# GPMC0_CFG register map
Vendor: Texas Instruments
Peripheral module from a debugger description file (folder J722S).
Registers are 32-bit, access not given, reset 0x0 unless marked. A register's access mark holds for its fields unless they carry their own. Offsets are as the file gives them; lines under a group give offsets from that group; [hi:lo] are bit positions; {n}, {i} and the like mark numbered series; 'fields as' and 'values as' point back to an identical list; <NAME> marks a mode.

## GPMC0_CFG
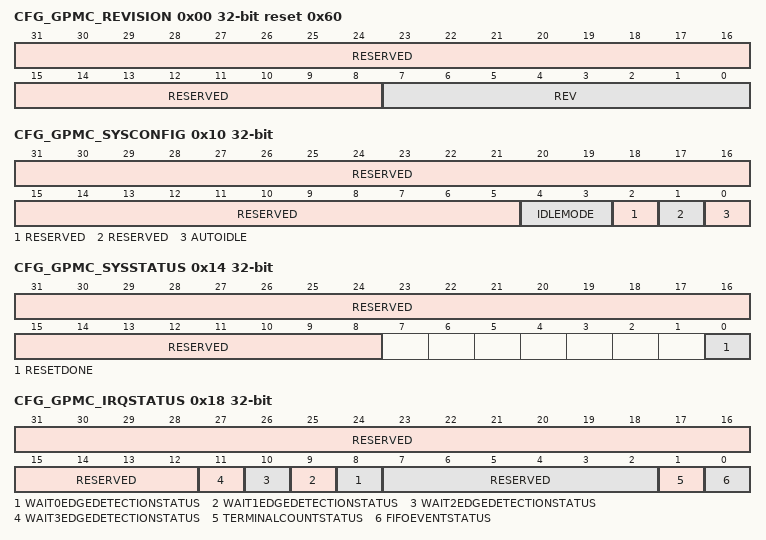
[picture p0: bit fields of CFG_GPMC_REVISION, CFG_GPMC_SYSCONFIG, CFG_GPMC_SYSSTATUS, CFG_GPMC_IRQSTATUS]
0x00 CFG_GPMC_REVISION reset 0x60 — This register contains the IP revision code
  [31:8] RESERVED — Reads returns 0 (access N/A)
  [7:0] REV ro — IP revision [7:4] Major revision [3:0] Minor revision Examples: 0x10 for 1.0, 0x21 for 2.1
0x10 CFG_GPMC_SYSCONFIG — This register controls the various parameters of the OCP interface
  [31:5] RESERVED — Write 0's for future compatibility Reads return 0 (access N/A)
  [4:3] IDLEMODE rw
  [2] RESERVED — Write 0 for future compatibility Reads returns 0 (access N/A)
  [1] RESERVED — This bit must be kept 0 for normal functioning of the IP. Do not set this bit to 1 (access N/A)
  [0] AUTOIDLE rw — Internal OCP clock gating strategy
0x14 CFG_GPMC_SYSSTATUS — This register provides status information about the module, excluding the interrupt status information
  [31:8] RESERVED — Reads returns 0 (access N/A)
  [0] RESETDONE ro — Internal reset monitoring
0x18 CFG_GPMC_IRQSTATUS — This interrupt status register regroups all the status of the module internal events that can generate an interrupt.
  [31:12] RESERVED — Write 0's for future compatibility. Read returns 0 (access N/A)
  [n+8] WAIT{n}EDGEDETECTIONSTATUS (n=0..3) — Status of the Wait{n} Edge Detection interrupt (access R/W1TC)
  [7:2] RESERVED — Write 0's for future compatibility. Read returns 0 (access N/A)
  [1] TERMINALCOUNTSTATUS — Status of the TerminalCountEvent interrupt (access R/W1TC)
  [0] FIFOEVENTSTATUS — Status of the FIFOEvent interrupt (access R/W1TC)
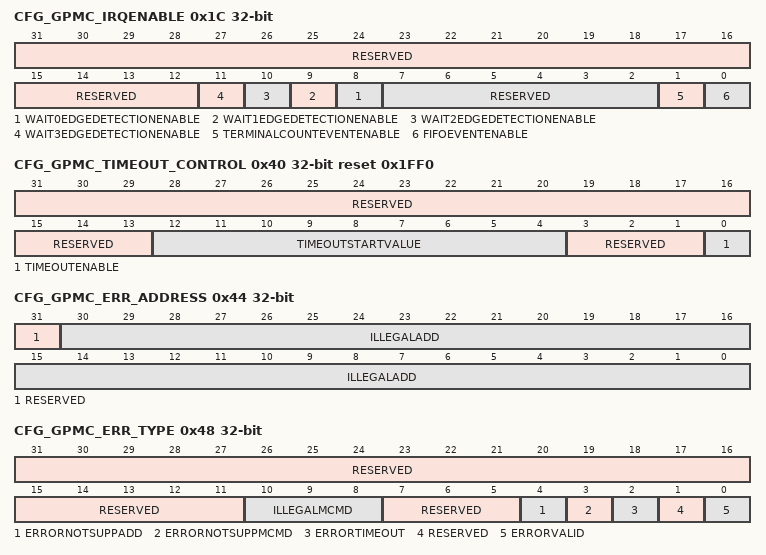
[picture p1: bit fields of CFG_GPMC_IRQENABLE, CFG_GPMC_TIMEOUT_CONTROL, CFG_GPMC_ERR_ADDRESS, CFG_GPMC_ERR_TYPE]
0x1C CFG_GPMC_IRQENABLE — The interrupt enable register allows to mask/unmask the module internal sources of interrupt, on a event-by-event basis.
  [31:12] RESERVED — Write 0's for future compatibility. Read returns 0 (access N/A)
  [n+8] WAIT{n}EDGEDETECTIONENABLE rw (n=0..3) — Enables the Wait{n} Edge Detection interrupt
  [7:2] RESERVED — Write 0's for future compatibility. Read returns 0 (access N/A)
  [1] TERMINALCOUNTEVENTENABLE rw — Enables TerminalCountEvent interrupt issuing in pre-fetch or write posting mode
  [0] FIFOEVENTENABLE rw — Enables the FIFOEvent interrupt
0x40 CFG_GPMC_TIMEOUT_CONTROL reset 0x1FF0 — The GPMC_TIMEOUT_CONTROL register allows the user to set the start value of the timeout counter
  [31:13] RESERVED — Write 0's for future compatibility. Read returns 0 (access N/A)
  [12:4] TIMEOUTSTARTVALUE rw — Start value of the time-out counter [0x000 corresponds to 0 GPMC.FCLK cycle, 0x001 corresponds to 1 GmpcClk cycle, &, 0x1FF corresponds to 511 GPMC.FCLK cyles.]
  [3:1] RESERVED — Write 0's for future compatibility. Read returns 0 (access N/A)
  [0] TIMEOUTENABLE rw — Enable bit of the TimeOut feature
0x44 CFG_GPMC_ERR_ADDRESS — The GPMC_ERR_ADDRESS register stores the address of the illegal access when an error occurs
  [31] RESERVED — Write 0's for future compatibility. Read returns 0 (access N/A)
  [30:0] ILLEGALADD ro — Address of illegal access : A30[0 for memory region, 1 for GPMC register region] and A29-A0[1 GBytes maximum]
0x48 CFG_GPMC_ERR_TYPE — The GPMC_ERR_TYPE register stores the type of error when an error occurs
  [31:11] RESERVED — Write 0's for future compatibility. Read returns 0 (access N/A)
  [10:8] ILLEGALMCMD ro — System Command of the transaction that caused the error
  [7:5] RESERVED — Write 0's for future compatibility. Read returns 0 (access N/A)
  [4] ERRORNOTSUPPADD ro — Not supported Address error
  [3] ERRORNOTSUPPMCMD ro — Not supported Command error
  [2] ERRORTIMEOUT ro — Time-out error
  [1] RESERVED — Write 0's for future compatibility. Read returns 0 (access N/A)
  [0] ERRORVALID — Error validity status - Must be explicitely cleared with a write 1 transaction (access R/W1TC)
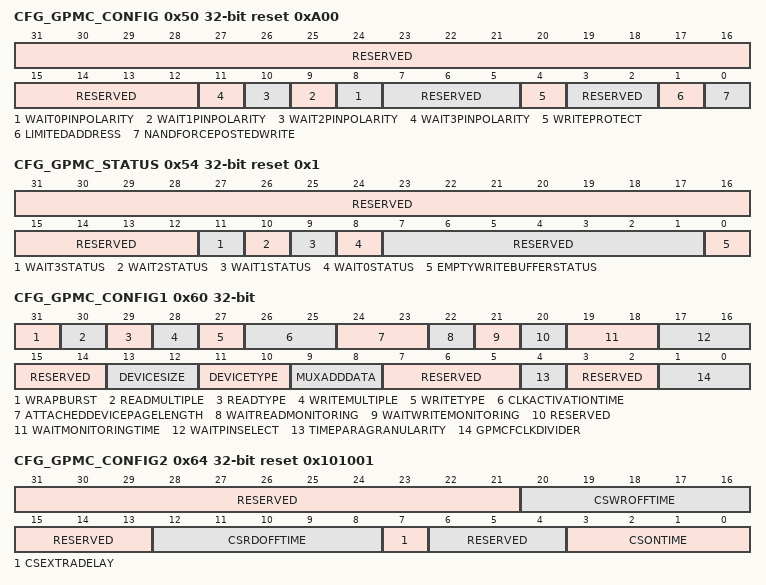
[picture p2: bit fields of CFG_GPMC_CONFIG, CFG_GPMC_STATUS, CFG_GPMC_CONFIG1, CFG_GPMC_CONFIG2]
0x50 CFG_GPMC_CONFIG reset 0xA00 — The configuration register allows global configuration of the GPMC
  [31:12] RESERVED — Write 0's for future compatibility. Read returns 0 (access N/A)
  [n+8] WAIT{n}PINPOLARITY rw (n=0..3) — Selects the polarity of input pin WAIT{n}
  [7:5] RESERVED — Write 0's for future compatibility. Read returns 0 (access N/A)
  [4] WRITEPROTECT rw — Controls the WP output pin level
  [3:2] RESERVED — Write 0's for future compatibility. Read returns 0 (access N/A)
  [1] LIMITEDADDRESS rw — Limited Address device support
  [0] NANDFORCEPOSTEDWRITE rw — Enables the Force Posted Write feature to NAND Cmd/Add/Data location
0x54 CFG_GPMC_STATUS reset 0x1 — The status register provides global status bits of the GPMC
  [31:12] RESERVED — Write 0's for future compatibility. Read returns 0 (access N/A)
  [11] WAIT3STATUS ro — Is a copy of input pin WAIT3. [Reset value is WAIT3 input pin sampled at IC reset]
  [10] WAIT2STATUS ro — Is a copy of input pin WAIT2. [Reset value is WAIT2 input pin sampled at IC reset]
  [9] WAIT1STATUS ro — Is a copy of input pin WAIT1. [Reset value is WAIT1 input pin sampled at IC reset]
  [8] WAIT0STATUS ro — Is a copy of input pin WAIT0. [Reset value is WAIT0 input pin sampled at IC reset]
  [7:1] RESERVED — Write 0's for future compatibility Reads returns 0 (access N/A)
  [0] EMPTYWRITEBUFFERSTATUS ro — Stores the empty status of the write buffer
0x60 CFG_GPMC_CONFIG1 — The configuration 1 register sets signal control parameters per chip select
  [31] WRAPBURST rw — Enables the wrapping burst capability. Must be set if the attached device is configured in wrapping burst
  [30] READMULTIPLE rw — Selects the read single or multiple access
  [29] READTYPE rw — Selects the read mode operation
  [28] WRITEMULTIPLE rw — Selects the write single or multiple access
  [27] WRITETYPE rw — Selects the write mode operation
  [26:25] CLKACTIVATIONTIME rw — Output GPMC.CLK activation time
  [24:23] ATTACHEDDEVICEPAGELENGTH rw — Specifies the attached device page [burst] length
  [22] WAITREADMONITORING rw — Selects the Wait monitoring configuration for Read accesses [Reset value is BOOTWAITEN input pin sampled at IC reset]
  [21] WAITWRITEMONITORING rw — Selects the Wait monitoring configuration for Write accesses
  [20] RESERVED — Write 0's for future compatibility. Read returns 0 (access N/A)
  [19:18] WAITMONITORINGTIME rw — Selects input pin Wait monitoring time
  [17:16] WAITPINSELECT rw — Selects the input WAIT pin for this chip select [Reset value is BOOTWAITSELECT input pin sampled at IC reset for CS0 and 0 for CS1-7]
  [15:14] RESERVED — Write 0's for future compatibility. Read returns 0 (access N/A)
  [13:12] DEVICESIZE rw — Selects the device size attached [Reset value is BOOTDEVICESIZE input pin sampled at IC reset for CS0 and 01 for CS1-7]
  [11:10] DEVICETYPE rw — Selects the attached device type
  [9:8] MUXADDDATA rw — Enables the Address and data multiplexed protocol [Reset value is CS0MUXDEVICE input pin sampled at IC reset for CS0 and 0 for CS1-7]
  [7:5] RESERVED — Write 0's for future compatibility. Read returns 0 (access N/A)
  [4] TIMEPARAGRANULARITY rw — Signals timing latencies scalar factor [Rd/WRCycleTime, AccessTime, PageBurstAccessTime, CSOnTime, CSRd/WrOffTime, ADVOnTime, ADVRd/WrOffTime, OEOnTime, OEOffTime, WEOnTime, WEOffTime, Cycle2CycleDelay, BusTurnAround, TimeOutStartValue]
  [3:2] RESERVED — Write 0's for future compatibility. Read returns 0 (access N/A)
  [1:0] GPMCFCLKDIVIDER rw — Divides the GPMC.FCLK clock
0x64 CFG_GPMC_CONFIG2 reset 0x101001 — Chip-select signal timing parameter configuration
  [31:21] RESERVED — Write 0's for future compatibility Reads returns 0 (access N/A)
  [20:16] CSWROFFTIME rw — CS# de-assertion time from start cycle time for write accesses [0x00 corresponds to 0 GPMC.FCLK cycle, 0x01 corresponds to 1 GPMC.FCLK cycle, &, 0x1F corresponds to 31 GPMC.FCLK cycles]
  [15:13] RESERVED — Write 0's for future compatibility. Read returns 0 (access N/A)
  [12:8] CSRDOFFTIME rw — CS# de-assertion time from start cycle time for read accesses [0x00 corresponds to 0 GPMC.FCLK cycle, 0x01 corresponds to 1 GPMC.FCLK cycle, &, 0x1F corresponds to 31 GPMC.FCLK cycles]
  [7] CSEXTRADELAY rw — CS# Add Extra Half GPMC.FCLK cycle
  [6:4] RESERVED — Write 0's for future compatibility. Read returns 0 (access N/A)
  [3:0] CSONTIME rw — CS# assertion time from start cycle time [0x0 corresponds to 0 GPMC.FCLK cycle, 0x1 corresponds to 1 GPMC.FCLK cycle, &, 0xF corresponds to 15 GPMC.FCLK cycles]
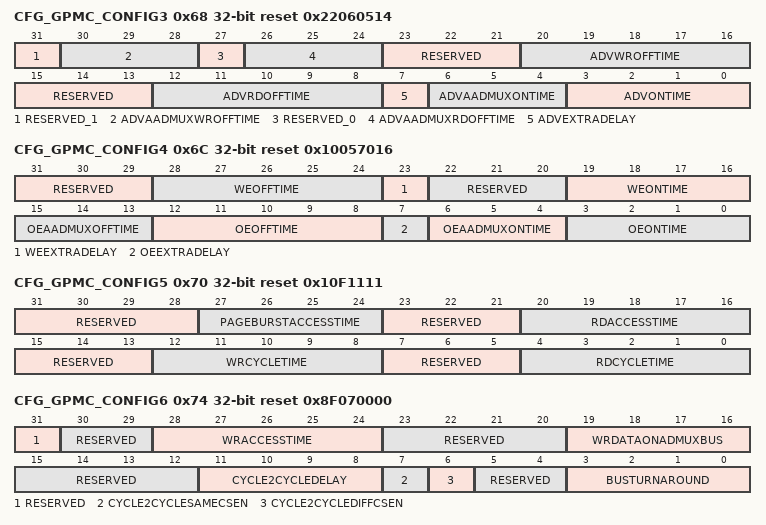
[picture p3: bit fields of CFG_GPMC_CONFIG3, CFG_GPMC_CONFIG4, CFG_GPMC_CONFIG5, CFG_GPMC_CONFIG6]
0x68 CFG_GPMC_CONFIG3 reset 0x22060514 — ADV# signal timing parameter configuration
  [31] RESERVED_1 ro — Write 0's for future compatibility. Read returns 0
  [30:28] ADVAADMUXWROFFTIME rw — ADV# de-assertion for first address phase when using the AAD-Mux protocol
  [27] RESERVED_0 ro — Write 0's for future compatibility. Read returns 0
  [26:24] ADVAADMUXRDOFFTIME rw — ADV# assertion for first address phase when using the AAD-Mux protocol
  [23:21] RESERVED — Write 0's for future compatibility. Read returns 0 (access N/A)
  [20:16] ADVWROFFTIME rw — ADV# de-assertion time from start cycle time for write accesses [0x00 corresponds to 0 GPMC.FCLK cycle, 0x01 corresponds to 1 GPMC.FCLK cycle, &, 0x1F corresponds to 31 GPMC.FCLK cycles]
  [15:13] RESERVED — Write 0's for future compatibility. Read returns 0 (access N/A)
  [12:8] ADVRDOFFTIME rw — ADV# de-assertion time from start cycle time for read accesses[0x00 corresponds to 0 GPMC.FCLK cycle, 0x01 corresponds to 1 GPMC.FCLK cycle, &, 0x1F corresponds to 31 GPMC.FCLK cycles]
  [7] ADVEXTRADELAY rw — ADV# Add Extra Half GPMC.FCLK cycle
  [6:4] ADVAADMUXONTIME rw — ADV# assertion for first address phase when using the AAD-Mux protocol
  [3:0] ADVONTIME rw — ADV# assertion time from start cycle time [0x0 corresponds to 0 GPMC.FCLK cycle, 0x1 corresponds to 1 GPMC.FCLK cycle, &, 0xF corresponds to 15 GPMC.FCLK cycles]
0x6C CFG_GPMC_CONFIG4 reset 0x10057016 — WE# and OE# signals timing parameter configuration
  [31:29] RESERVED ro — Write 0's for future compatibility. Read returns 0
  [28:24] WEOFFTIME rw — WE# de-assertion time from start cycle time [0x00 corresponds to 0 GPMC.FCLK cycle, 0x01 corresponds to 1 GPMC.FCLK cycle, &, 0x1F corresponds to 31 GPMC.FCLK cycles]
  [23] WEEXTRADELAY rw — WE# Add Extra Half GPMC.FCLK cycle
  [22:20] RESERVED — Write 0's for future compatibility. Read returns 0 (access N/A)
  [19:16] WEONTIME rw — WE# assertion time from start cycle time [0x0 corresponds to 0 GPMC.FCLK cycle, 0x1 corresponds to 1 GPMC.FCLK cycle, &, 0xF corresponds to 15 GPMC.FCLK cycles]
  [15:13] OEAADMUXOFFTIME rw — OE# de-assertion time for the first address phase in an AAD-Mux access
  [12:8] OEOFFTIME rw — OE# de-assertion time from start cycle time [0x00 corresponds to 0 GPMC.FCLK cycle, 0x01 corresponds to 1 GPMC.FCLK cycle, &, 0x1F corresponds to 31 GPMC.FCLK cycles]
  [7] OEEXTRADELAY rw — OE# Add Extra Half GPMC.FCLK cycle
  [6:4] OEAADMUXONTIME rw — OE# assertion time for the first address phase in an AAD-Mux access
  [3:0] OEONTIME rw — OE# assertion time from start cycle time [0x0 corresponds to 0 GPMC.FCLK cycle, 0x1 corresponds to 1 GPMC.FCLK cycle, &, 0xF corresponds to 15 GPMC.FCLK cycles]
0x70 CFG_GPMC_CONFIG5 reset 0x10F1111 — RdAccessTime and CycleTime timing parameters configuration
  [31:28] RESERVED — Write 0's for future compatibility. Read returns 0 (access N/A)
  [27:24] PAGEBURSTACCESSTIME rw — Delay between successive words in a multiple access [0x0 corresponds to 0 GPMC.FCLK cycle, 0x1 corresponds to 1 GPMC.FCLK cycle, &, 0xF corresponds to 15 GPMC.FCLK cycles]
  [23:21] RESERVED — Write 0's for future compatibility. Read returns 0 (access N/A)
  [20:16] RDACCESSTIME rw — Delay between start cycle time and first data valid [0x00 corresponds to 0 GPMC.FCLK cycle, 0x01 corresponds to 1 GPMC.FCLK cycle, &, 0x1F corresponds to 31 GPMC.FCLK cycles]
  [15:13] RESERVED — Write 0's for future compatibility Reads returns 0 (access N/A)
  [12:8] WRCYCLETIME rw — Total write cycle time [0x00 corresponds to 0 GPMC.FCLK cycle, 0x01 corresponds to 1 GPMC.FCLK cycle, &, 0x1F corresponds to 31 GPMC.FCLK cycles]
  [7:5] RESERVED — Write 0's for future compatibility. Read returns 0 (access N/A)
  [4:0] RDCYCLETIME rw — Total read cycle time [0x00 corresponds to 0 GPMC.FCLK cycle, 0x01 corresponds to 1 GPMC.FCLK cycle, &, 0x1F corresponds to 31 GPMC.FCLK cycles]
0x74 CFG_GPMC_CONFIG6 reset 0x8F070000 — WrAccessTime, WrDataOnADmuxBus, Cycle2Cycle and BusTurnAround parameters configuration
  [31] RESERVED rw — TI Internal use - Do not modify
  [30:29] RESERVED — Write 0's for future compatibility. Read returns 0 (access N/A)
  [28:24] WRACCESSTIME rw — Delay from StartAccessTime to the GPMC.FCLK rising edge corresponding the the GPMC.CLK rising edge used by the attached memory for the first data capture [0x00 corresponds to 0 GPMC.FCLK cycle, 0x01 corresponds to 1 GPMC.FCLK cycle, &, 0x1F corresponds to 31 GPMC.FCLK cycles]
  [23:20] RESERVED — Write 0's for future compatibility. Read returns 0 (access N/A)
  [19:16] WRDATAONADMUXBUS rw — Specifies on which GPMC.FCLK rising edge the first data of the synchronous burst write is driven in the add/data mux bus
  [15:12] RESERVED — Write 0's for future compatibility. Read returns 0 (access N/A)
  [11:8] CYCLE2CYCLEDELAY rw — Chip select high pulse delay between two successive accesses [0x0 corresponds to 0 GPMC.FCLK cycle, 0x1 corresponds to 1 GPMC.FCLK cycle, &, 0xF corresponds to 15 GPMC.FCLK cycles]
  [7] CYCLE2CYCLESAMECSEN rw — Add Cycle2CycleDelay between two successive accesses to the same chip-select [any access type]
  [6] CYCLE2CYCLEDIFFCSEN rw — Add Cycle2CycleDelay between two successive accesses to a different chip-select [any access type]
  [5:4] RESERVED — Write 0's for future compatibility Reads returns 0 (access N/A)
  [3:0] BUSTURNAROUND rw — Bus turn around latency between two successive accesses to the same chip-select [rd to wr] or to a different chip-select [read to read and read to write] [0x0 corresponds to 0 GPMC.FCLK cycle, 0x1 corresponds to 1 GPMC.FCLK cycle, &, 0xF corresponds to 15 GPMC.FCLK cycles]
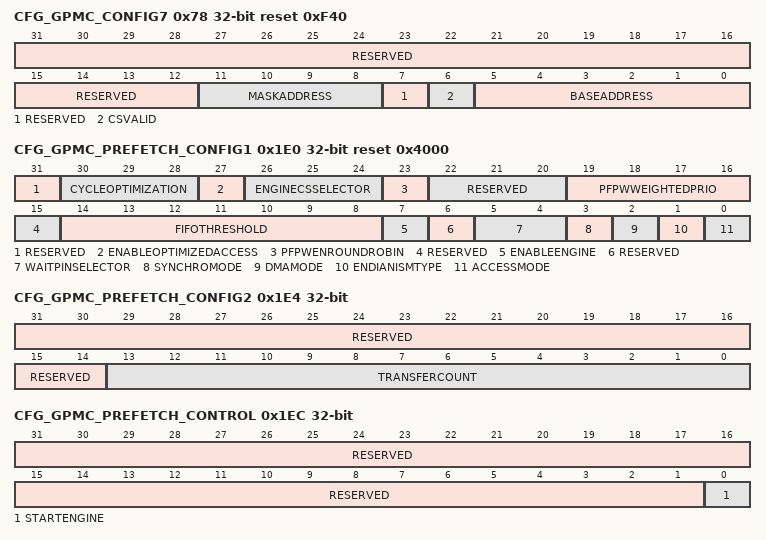
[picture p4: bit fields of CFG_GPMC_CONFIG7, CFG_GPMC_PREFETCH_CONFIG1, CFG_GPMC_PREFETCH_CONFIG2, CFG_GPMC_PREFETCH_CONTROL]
0x78 CFG_GPMC_CONFIG7 reset 0xF40 — Chip-select address mapping configuration Note: For CS0, the register reset is 0xf40 while for all the other instances CS1-CS7, the reset is 0xf00.
  [31:12] RESERVED — Write 0's for future compatibility. Read returns 0 (access N/A)
  [11:8] MASKADDRESS rw — Chip-select mask address
  [7] RESERVED — Write 0's for future compatibility. Read returns 0 (access N/A)
  [6] CSVALID rw — Chip-select enable [reset value is 1 for CS0 and 0 for CS1-7]
  [5:0] BASEADDRESS rw — Chip-select base address
0x7C CFG_GPMC_NAND_COMMAND wo — This Register is not a true register, just a address location.
  [31:0] GPMC_NAND_COMMAND_0
0x80 CFG_GPMC_NAND_ADDRESS wo — This Register is not a true register, just a address location.
  [31:0] GPMC_NAND_ADDRESS_0
0x84 CFG_GPMC_NAND_DATA rw — This Register is not a true register, just a address location.
  [31:0] GPMC_NAND_DATA_0
0x1E0 CFG_GPMC_PREFETCH_CONFIG1 reset 0x4000 — Prefetch engine configuration 1
  [31] RESERVED — Write 0's for future compatibility. Read returns 0 (access N/A)
  [30:28] CYCLEOPTIMIZATION rw — Define the number of GPMC.FCLK cycles to be substracted from RdCycleTime, WrCycleTime, AccessTime, CSRdOffTime, CSWrOffTime, ADVRdOffTime, ADVWrOffTime, OEOffTime, WEOffTime [0x0 corresponds to 0 GPMC.FCLK cycle, 0x1 corresponds to 1 GPMC.FCLK cycle, &, 0x7 corresponds to 7 GPMC.FCLK cycles]
  [27] ENABLEOPTIMIZEDACCESS rw — Enables access cycle optimization
  [26:24] ENGINECSSELECTOR rw — Selects the CS where Prefetch Postwrite engine is active [0x0 corresponds toCS0, 0x1 corresponds to CS1, &, 0x7 corresponds to CS7]
  [23] PFPWENROUNDROBIN rw — Enables the PFPW RoundRobin arbitration
  [22:20] RESERVED — Write 0's for future compatibility. Read returns 0 (access N/A)
  [19:16] PFPWWEIGHTEDPRIO rw — When an arbitration occurs between a direct memory access and a PFPW engine access, the direct memory access is always serviced. If the PFPWEnRoundRobin is enabled, 0x0 means : the next access is granted to the PFPW engine, 0x1 means : the two next accesses are granted to the PFPW engine, ..., 0xF means : the 16 next accesses are granted to the PFPW engine.
  [15] RESERVED — Write 0's for future compatibility. Read returns 0 (access N/A)
  [14:8] FIFOTHRESHOLD rw — Selects the maximum number of bytes read from the FIFO or written to the FIFO by the host on a DMA or interrupt request [0x00 corresponds to 0 byte, 0x01 corresponds to 1 byte, &, 0x40 corresponds to 64 bytes]
  [7] ENABLEENGINE rw — Enables the Prefetch Postwite engine
  [6] RESERVED — Write 0's for future compatibility. Read returns 0 (access N/A)
  [5:4] WAITPINSELECTOR rw — Select which wait pin edge detector should start the engine in synchronized mode
  [3] SYNCHROMODE rw — Selects when the engine starts the access to CS
  [2] DMAMODE rw — Selects interrupt synchronization or DMA request synchronization
  [1] ENDIANISMTYPE rw — Selects endianism for prefetch data [0x0 for Little Endian and 0x1 for Big Endian]
  [0] ACCESSMODE rw — Selects pre-fetch read or write posting accesses
0x1E4 CFG_GPMC_PREFETCH_CONFIG2 — Prefetch engine configuration 2
  [31:14] RESERVED — Write 0's for future compatibility. Read returns 0 (access N/A)
  [13:0] TRANSFERCOUNT rw — Selects the number of bytes to be read or written by the engine to the selected CS [0x0000 corresponds to 0 byte, 0x0001 corresponds to 1 byte, &, 0x2000 corresponds to 8 Kbytes]
0x1EC CFG_GPMC_PREFETCH_CONTROL — Prefetch engine control
  [31:1] RESERVED — Write 0's for future compatibility. Read returns 0 (access N/A)
  [0] STARTENGINE rw — Resets the FIFO pointer and starts the engine
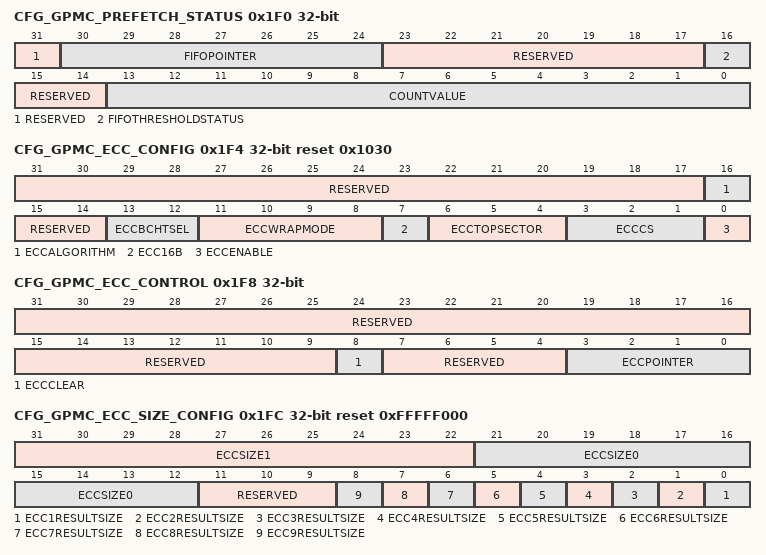
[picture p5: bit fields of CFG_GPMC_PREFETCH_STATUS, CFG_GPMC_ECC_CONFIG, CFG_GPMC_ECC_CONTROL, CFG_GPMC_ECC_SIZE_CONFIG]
0x1F0 CFG_GPMC_PREFETCH_STATUS — Prefetch engine status
  [31] RESERVED — Write 0's for future compatibility. Read returns 0 (access N/A)
  [30:24] FIFOPOINTER ro — Number of available bytes to be read or number of free empty byte places to be written [0x00 corresponds to 0 byte available to be read or 0 free empty place to be written, &, 0x40 corresponds to 64 bytes available to be read or 64 empty places to be written]
  [23:17] RESERVED — Write 0's for future compatibility. Read returns 0 (access N/A)
  [16] FIFOTHRESHOLDSTATUS ro — Set when FIFOPointer exceeds FIFOThreshold value
  [15:14] RESERVED — Write 0's for future compatibility. Read returns 0 (access N/A)
  [13:0] COUNTVALUE ro — Number of remaining bytes to be read or to be written by the engine according to the TransferCount value [0x0000 corresponds to 0 byte remaining to be read or to be written, 0x0001 corresponds to 1 byte remaining to be read or to be written, &, 0x2000 corresponds to 8 Kbytes remaining to be read or to be written]
0x1F4 CFG_GPMC_ECC_CONFIG reset 0x1030 — ECC configuration
  [31:17] RESERVED — Write 0's for future compatibility. Read returns 0 (access N/A)
  [16] ECCALGORITHM rw — ECC algorithm used 0x0: Hamming code 0x1: BCH code
  [15:14] RESERVED — Write 0's for future compatibility. Read returns 0 (access N/A)
  [13:12] ECCBCHTSEL rw — Error correction capability used for BCH 0x0: up to 4 bits error correction [t = 4] 0x1: up to 8 bits error correction [t=8] 0x2: up to 16 bits error correction [t=16] 0x3: reserved
  [11:8] ECCWRAPMODE rw — Spare area organization definition for the BCH algorithm. See the BCH syndrome/parity calculator module functional specification for more details
  [7] ECC16B rw — Selects an ECC calculated on 16 columns
  [6:4] ECCTOPSECTOR rw — Number of sectors to process with the BCH algorithm 0x0: 1 sector [512kB page] 0x1: 2 sectors ... 0x3: 4 sectors [2kB page] ... 0x7: 8 sectors [4kB page]
  [3:1] ECCCS rw — Selects the CS where ECC is computed
  [0] ECCENABLE rw — Enables the ECC feature
0x1F8 CFG_GPMC_ECC_CONTROL — ECC control
  [31:9] RESERVED — Write 0's for future compatibility. Read returns 0 (access N/A)
  [8] ECCCLEAR — Clear all ECC result registers [Reads returns 0 - Writes 1 to this field clear all ECC result registers - Writes 0 are ignored] (access R/W1TC)
  [7:4] RESERVED — Write 0's for future compatibility. Read returns 0 (access N/A)
  [3:0] ECCPOINTER rw — Selects ECC result register [Reads to this field give the dynamic position of the ECC pointer - Writes to this field select the ECC result register where the first ECC computation will be stored]; Other enums: writing other values disables the ECC engine [ECCEnable bit of GPMC_ECC_CONFIG set to 0]
0x1FC CFG_GPMC_ECC_SIZE_CONFIG reset 0xFFFFF000 — ECC size
  [31:22] ECCSIZE1 rw — Defines ECC size 1 [For Hamming Code: 0x000 corresponds to 2 Bytes, 0x001 corresponds to 4 Bytes, 0x002 corresponds to 6 Bytes, 0x003 corresponds to 8 Bytes, &, 0x0FF corresponds to 512 Bytes. Max supported value is 0x0FF.] [For BCH: 0x000 corresponds to 0 nibbles, 0x001 corresponds to 1 nibble, 0x002 corresponds to 2 nibbles, 0x003 corresponds to 3 nibbles, &, 0x3FF corresponds to 1023 nibbles.]
  [21:12] ECCSIZE0 rw — Defines ECC size 0 [For Hamming Code: 0x000 corresponds to 2 Bytes, 0x001 corresponds to 4 Bytes, 0x002 corresponds to 6 Bytes, 0x003 corresponds to 8 Bytes, &, 0x0FF corresponds to 512 Bytes. Max supported value is 0x0FF.] [For BCH: 0x000 corresponds to 0 nibbles, 0x001 corresponds to 1 nibble, 0x002 corresponds to 2 nibbles, 0x003 corresponds to 3 nibbles, &, 0x3FF corresponds to 1023 nibbles.]
  [11:9] RESERVED — Write 0's for future compatibility. Read returns 0 (access N/A)
  [n-1] ECC{n}RESULTSIZE rw (n=1..9) — Selects ECC size for ECC {n} result register
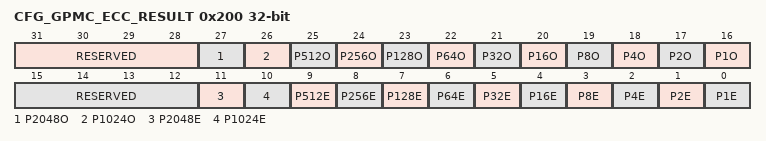
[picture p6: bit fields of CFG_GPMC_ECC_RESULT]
0x200 CFG_GPMC_ECC_RESULT — ECC result register
  [31:28] RESERVED — Write 0's for future compatibility. Read returns 0 (access N/A)
  [27] P2048O ro — Odd Row Parity bit 2048, only used for ECC computed on 512 Bytes
  [26] P1024O ro — Odd Row Parity bit 1024
  [25] P512O ro — Odd Row Parity bit 512
  [24] P256O ro — Odd Row Parity bit 256
  [23] P128O ro — Odd Row Parity bit 128
  [22] P64O ro — Odd Row Parity bit 64
  [21] P32O ro — Odd Row Parity bit 32
  [20] P16O ro — Odd Row Parity bit 16
  [19] P8O ro — Odd Row Parity bit 8
  [18] P4O ro — Odd Column Parity bit 4
  [17] P2O ro — Odd Column Parity bit 2
  [16] P1O ro — Odd Column Parity bit 1
  [15:12] RESERVED — Write 0's for future compatibility. Read returns 0 (access N/A)
  [11] P2048E ro — Even Row Parity bit 2048, only used for ECC computed on 512 Bytes
  [10] P1024E ro — Even Row Parity bit 1024
  [9] P512E ro — Even Row Parity bit 512
  [8] P256E ro — Even Row Parity bit 256
  [7] P128E ro — Even Row Parity bit 128
  [6] P64E ro — Even Row Parity bit 64
  [5] P32E ro — Even Row Parity bit 32
  [4] P16E ro — Even Row Parity bit 16
  [3] P8E ro — Even Row Parity bit 8
  [2] P4E ro — Even Column Parity bit 4
  [1] P2E ro — Even Column Parity bit 2
  [0] P1E ro — Even Column Parity bit 1
{0x240+4i} CFG_GPMC_BCH_RESULT_{i} ro (i=0..3) — BCH ECC result, bits {32i} to {32i+31}
  [31:0] BCH_RESULT_{i}
0x2D0 CFG_GPMC_BCH_SWDATA wo — This register is used to directly pass data to the BCH ECC calculator without accessing the actual NAND flash interface.
  [15:0] BCH_DATA — Data to be included in the BCH calculation. Only bits 0 to 7 are taken into account if the calculator is configured to use 8 bits data [ECC16B = 0]
0x300 CFG_GPMC_BCH_RESULT_4 ro — BCH ECC result, bits 128 to 159
  [31:0] BCH_RESULT_4
0x304 CFG_GPMC_BCH_RESULT_5 ro — BCH ECC result, bits 160 to 191
  [31:0] BCH_RESULT_5
0x308 CFG_GPMC_BCH_RESULT_6 ro — BCH ECC result, bits 192 to 207
  [15:0] BCH_RESULT_6
